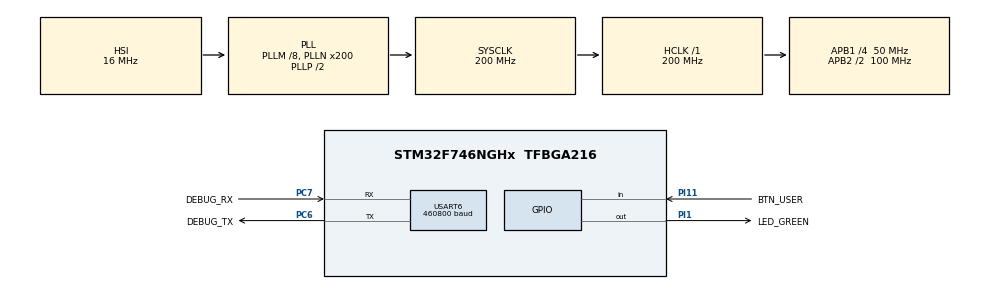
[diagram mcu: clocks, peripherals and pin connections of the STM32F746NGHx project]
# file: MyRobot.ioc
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Mcu.Family=STM32F7
Mcu.Name=STM32F746NGHx
Mcu.Package=TFBGA216
NVIC.PriorityGroup=NVIC_PRIORITYGROUP_4
NVIC.USART6_IRQn=true\:0\:0\:false\:false\:true\:true
PC6.GPIO_Label=DEBUG_TX
PC6.Mode=Asynchronous
PC6.Signal=USART6_TX
PC7.GPIO_Label=DEBUG_RX
PC7.Mode=Asynchronous
PC7.Signal=USART6_RX
PH0/OSC_IN.Mode=HSE-External-Oscillator
PH0/OSC_IN.Signal=RCC_OSC_IN
PH1/OSC_OUT.Mode=HSE-External-Oscillator
PH1/OSC_OUT.Signal=RCC_OSC_OUT
PI1.GPIO_Label=LED_GREEN
PI1.Signal=GPIO_Output
PI11.GPIO_Label=BTN_USER
PI11.Signal=GPIO_Input
ProjectManager.HeapSize=0x200
ProjectManager.StackSize=0x800
ProjectManager.TargetToolchain=TrueSTUDIO
RCC.AHBFreq_Value=200000000
RCC.APB1CLKDivider=RCC_HCLK_DIV4
RCC.APB1Freq_Value=50000000
RCC.APB1TimFreq_Value=100000000
RCC.APB2CLKDivider=RCC_HCLK_DIV2
RCC.APB2Freq_Value=100000000
RCC.APB2TimFreq_Value=200000000
RCC.CortexFreq_Value=200000000
RCC.HCLKFreq_Value=200000000
RCC.HSE_VALUE=25000000
RCC.HSI_VALUE=16000000
RCC.LSE_VALUE=32768
RCC.PLLM=8
RCC.PLLN=200
RCC.SYSCLKFreq_VALUE=200000000
RCC.SYSCLKSource=RCC_SYSCLKSOURCE_PLLCLK
RCC.USBFreq_Value=200000000
RCC.VCOOutputFreq_Value=400000000
USART6.BaudRate=460800
USART6.VirtualMode-Asynchronous=VM_ASYNC
board=custom

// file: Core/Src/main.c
/* USER CODE BEGIN Header */
/**
  ******************************************************************************
  * @file           : main.c
  * @brief          : Main program body
  ******************************************************************************
  ** This notice applies to any and all portions of this file
  * that are not between comment pairs USER CODE BEGIN and
  * USER CODE END. Other portions of this file, whether
  * inserted by the user or by software development tools
  * are owned by their respective copyright owners.
  *
  * COPYRIGHT(c) 2019 STMicroelectronics
  *
  * Redistribution and use in source and binary forms, with or without modification,
  * are permitted provided that the following conditions are met:
  *   1. Redistributions of source code must retain the above copyright notice,
  *      this list of conditions and the following disclaimer.
  *   2. Redistributions in binary form must reproduce the above copyright notice,
  *      this list of conditions and the following disclaimer in the documentation
  *      and/or other materials provided with the distribution.
  *   3. Neither the name of STMicroelectronics nor the names of its contributors
  *      may be used to endorse or promote products derived from this software
  *      without specific prior written permission.
  *
  * THIS SOFTWARE IS PROVIDED BY THE COPYRIGHT HOLDERS AND CONTRIBUTORS "AS IS"
  * AND ANY EXPRESS OR IMPLIED WARRANTIES, INCLUDING, BUT NOT LIMITED TO, THE
  * IMPLIED WARRANTIES OF MERCHANTABILITY AND FITNESS FOR A PARTICULAR PURPOSE ARE
  * DISCLAIMED. IN NO EVENT SHALL THE COPYRIGHT HOLDER OR CONTRIBUTORS BE LIABLE
  * FOR ANY DIRECT, INDIRECT, INCIDENTAL, SPECIAL, EXEMPLARY, OR CONSEQUENTIAL
  * DAMAGES (INCLUDING, BUT NOT LIMITED TO, PROCUREMENT OF SUBSTITUTE GOODS OR
  * SERVICES; LOSS OF USE, DATA, OR PROFITS; OR BUSINESS INTERRUPTION) HOWEVER
  * CAUSED AND ON ANY THEORY OF LIABILITY, WHETHER IN CONTRACT, STRICT LIABILITY,
  * OR TORT (INCLUDING NEGLIGENCE OR OTHERWISE) ARISING IN ANY WAY OUT OF THE USE
  * OF THIS SOFTWARE, EVEN IF ADVISED OF THE POSSIBILITY OF SUCH DAMAGE.
  *
  ******************************************************************************
  */
/* USER CODE END Header */

#include "main.h"

UART_HandleTypeDef huart6;

void SystemClock_Config(void);
static void MX_GPIO_Init(void);
static void MX_USART6_UART_Init(void);

int main(void)
{

  /* MCU Configuration--------------------------------------------------------*/

  /* Reset of all peripherals, Initializes the Flash interface and the Systick. */
  HAL_Init();

  /* Configure the system clock */
  SystemClock_Config();

  /* Initialize all configured peripherals */
  MX_GPIO_Init();
  MX_USART6_UART_Init();
  /* USER CODE BEGIN 2 */
  __HAL_UART_ENABLE_IT(&huart6, UART_IT_RXNE);
  /* USER CODE END 2 */

  /* Infinite loop */
  while (1)
  {
	HAL_Delay( 1000 );
	HAL_GPIO_TogglePin(LED_GREEN_GPIO_Port, LED_GREEN_Pin);
  }
}

void SystemClock_Config(void)
{
  RCC_OscInitTypeDef RCC_OscInitStruct = {0};
  RCC_ClkInitTypeDef RCC_ClkInitStruct = {0};
  RCC_PeriphCLKInitTypeDef PeriphClkInitStruct = {0};

  /**Configure the main internal regulator output voltage
  */
  __HAL_RCC_PWR_CLK_ENABLE();
  __HAL_PWR_VOLTAGESCALING_CONFIG(PWR_REGULATOR_VOLTAGE_SCALE1);
  /**Initializes the CPU, AHB and APB busses clocks
  */
  RCC_OscInitStruct.OscillatorType = RCC_OSCILLATORTYPE_HSI;
  RCC_OscInitStruct.HSIState = RCC_HSI_ON;
  RCC_OscInitStruct.HSICalibrationValue = RCC_HSICALIBRATION_DEFAULT;
  RCC_OscInitStruct.PLL.PLLState = RCC_PLL_ON;
  RCC_OscInitStruct.PLL.PLLSource = RCC_PLLSOURCE_HSI;
  RCC_OscInitStruct.PLL.PLLM = 8;
  RCC_OscInitStruct.PLL.PLLN = 200;
  RCC_OscInitStruct.PLL.PLLP = RCC_PLLP_DIV2;
  RCC_OscInitStruct.PLL.PLLQ = 2;
  if (HAL_RCC_OscConfig(&RCC_OscInitStruct) != HAL_OK)
  {
    Error_Handler();
  }
  /**Activate the Over-Drive mode
  */
  if (HAL_PWREx_EnableOverDrive() != HAL_OK)
  {
    Error_Handler();
  }
  /**Initializes the CPU, AHB and APB busses clocks
  */
  RCC_ClkInitStruct.ClockType = RCC_CLOCKTYPE_HCLK|RCC_CLOCKTYPE_SYSCLK
                              |RCC_CLOCKTYPE_PCLK1|RCC_CLOCKTYPE_PCLK2;
  RCC_ClkInitStruct.SYSCLKSource = RCC_SYSCLKSOURCE_PLLCLK;
  RCC_ClkInitStruct.AHBCLKDivider = RCC_SYSCLK_DIV1;
  RCC_ClkInitStruct.APB1CLKDivider = RCC_HCLK_DIV4;
  RCC_ClkInitStruct.APB2CLKDivider = RCC_HCLK_DIV2;

  if (HAL_RCC_ClockConfig(&RCC_ClkInitStruct, FLASH_LATENCY_6) != HAL_OK)
  {
    Error_Handler();
  }
  PeriphClkInitStruct.PeriphClockSelection = RCC_PERIPHCLK_USART6;
  PeriphClkInitStruct.Usart6ClockSelection = RCC_USART6CLKSOURCE_PCLK2;
  if (HAL_RCCEx_PeriphCLKConfig(&PeriphClkInitStruct) != HAL_OK)
  {
    Error_Handler();
  }
}

static void MX_USART6_UART_Init(void)
{

  huart6.Instance = USART6;
  huart6.Init.BaudRate = 460800;
  huart6.Init.WordLength = UART_WORDLENGTH_8B;
  huart6.Init.StopBits = UART_STOPBITS_1;
  huart6.Init.Parity = UART_PARITY_NONE;
  huart6.Init.Mode = UART_MODE_TX_RX;
  huart6.Init.HwFlowCtl = UART_HWCONTROL_NONE;
  huart6.Init.OverSampling = UART_OVERSAMPLING_16;
  huart6.Init.OneBitSampling = UART_ONE_BIT_SAMPLE_DISABLE;
  huart6.AdvancedInit.AdvFeatureInit = UART_ADVFEATURE_NO_INIT;
  if (HAL_UART_Init(&huart6) != HAL_OK)
  {
    Error_Handler();
  }

}

static void MX_GPIO_Init(void)
{
  GPIO_InitTypeDef GPIO_InitStruct = {0};

  /* GPIO Ports Clock Enable */
  __HAL_RCC_GPIOI_CLK_ENABLE();
  __HAL_RCC_GPIOH_CLK_ENABLE();
  __HAL_RCC_GPIOC_CLK_ENABLE();

  /*Configure GPIO pin Output Level */
  HAL_GPIO_WritePin(LED_GREEN_GPIO_Port, LED_GREEN_Pin, GPIO_PIN_RESET);

  /*Configure GPIO pin : LED_GREEN_Pin */
  GPIO_InitStruct.Pin = LED_GREEN_Pin;
  GPIO_InitStruct.Mode = GPIO_MODE_OUTPUT_PP;
  GPIO_InitStruct.Pull = GPIO_NOPULL;
  GPIO_InitStruct.Speed = GPIO_SPEED_FREQ_LOW;
  HAL_GPIO_Init(LED_GREEN_GPIO_Port, &GPIO_InitStruct);

  /*Configure GPIO pin : BTN_USER_Pin */
  GPIO_InitStruct.Pin = BTN_USER_Pin;
  GPIO_InitStruct.Mode = GPIO_MODE_INPUT;
  GPIO_InitStruct.Pull = GPIO_NOPULL;
  HAL_GPIO_Init(BTN_USER_GPIO_Port, &GPIO_InitStruct);

}

void Error_Handler(void)
{
}

/************************ (C) COPYRIGHT STMicroelectronics *****END OF FILE****/
